AUTOSAR XML (schema 314)
package /ComponentType
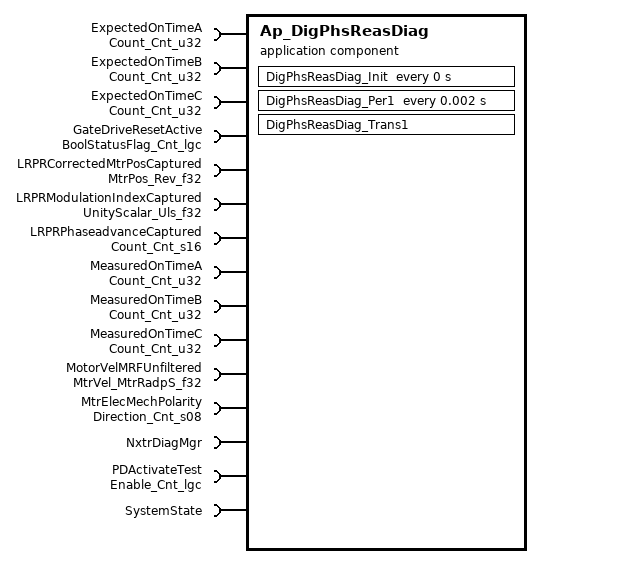
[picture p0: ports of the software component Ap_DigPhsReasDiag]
  application software component type Ap_DigPhsReasDiag
    15 x require port:
      ExpectedOnTimeA: unqueued-receiver-com-spec{data-element=Cnt_u32, init-value=D_ZERO_CNT_U32}, required-interface=Count_Cnt_u32
      ExpectedOnTimeB: unqueued-receiver-com-spec{data-element=Cnt_u32, init-value=D_ZERO_CNT_U32}, required-interface=Count_Cnt_u32
      ExpectedOnTimeC: unqueued-receiver-com-spec{data-element=Cnt_u32, init-value=D_ZERO_CNT_U32}, required-interface=Count_Cnt_u32
      GateDriveResetActive: unqueued-receiver-com-spec{data-element=Cnt_lgc, init-value=D_FALSE_CNT_LGC}, required-interface=BoolStatusFlag_Cnt_lgc
      LRPRCorrectedMtrPosCaptured: unqueued-receiver-com-spec{data-element=Rev_f32, init-value=D_ZERO_ULS_F32}, required-interface=MtrPos_Rev_f32
      LRPRModulationIndexCaptured: unqueued-receiver-com-spec{data-element=Uls_f32, init-value=D_ZERO_ULS_F32}, required-interface=UnityScalar_Uls_f32
      LRPRPhaseadvanceCaptured: unqueued-receiver-com-spec{data-element=Cnt_s16, init-value=D_ZERO_CNT_S16}, required-interface=Count_Cnt_s16
      MeasuredOnTimeA: unqueued-receiver-com-spec{data-element=Cnt_u32, init-value=D_ZERO_CNT_U32}, required-interface=Count_Cnt_u32
      MeasuredOnTimeB: unqueued-receiver-com-spec{data-element=Cnt_u32, init-value=D_ZERO_CNT_U32}, required-interface=Count_Cnt_u32
      MeasuredOnTimeC: unqueued-receiver-com-spec{data-element=Cnt_u32, init-value=D_ZERO_CNT_U32}, required-interface=Count_Cnt_u32
      MotorVelMRFUnfiltered: unqueued-receiver-com-spec{data-element=MtrRadpS_f32, init-value=D_ZERO_ULS_F32}, required-interface=MtrVel_MtrRadpS_f32
      MtrElecMechPolarity: unqueued-receiver-com-spec{data-element=Cnt_s08, init-value=D_ZERO_CNT_S8}, required-interface=Direction_Cnt_s08
      NxtrDiagMgr: required-com-specs=[GetNTCActive, GetNTCFailed, GetNTCStatus, SetNTCStatus], required-interface=NxtrDiagMgr
      PDActivateTest: unqueued-receiver-com-spec{data-element=Cnt_lgc, init-value=D_FALSE_CNT_LGC}, required-interface=Enable_Cnt_lgc
      SystemState: required-interface=SystemState
  internal behavior Ap_DigPhsReasDiag_InternalBehavior: component=Ap_DigPhsReasDiag
    timing event DigPhsReasDiag_InitEvent: start-on-event=DigPhsReasDiag_Init, period=0
    timing event TMT_DigPhsReasDiag_Per1: mode-dependency=dependent-on-mode=[SystemState.Mode.DISABLE, SystemState.Mode.OFF, SystemState.Mode.WARMINIT], start-on-event=DigPhsReasDiag_Per1, period=0.002
    mode switch event MST_DigPhsReasDiag_Trans1_0: start-on-event=DigPhsReasDiag_Trans1, activation=ENTRY, mode=SystemState.Mode.OPERATE
    port-api-options:
      enable-take-address=false, indirect-api=false, port=ExpectedOnTimeA
      enable-take-address=false, indirect-api=false, port=ExpectedOnTimeB
      enable-take-address=false, indirect-api=false, port=ExpectedOnTimeC
      enable-take-address=false, indirect-api=false, port=GateDriveResetActive
      enable-take-address=false, indirect-api=false, port=LRPRCorrectedMtrPosCaptured
      enable-take-address=false, indirect-api=false, port=LRPRModulationIndexCaptured
      enable-take-address=false, indirect-api=false, port=LRPRPhaseadvanceCaptured
      enable-take-address=false, indirect-api=false, port=MeasuredOnTimeA
      enable-take-address=false, indirect-api=false, port=MeasuredOnTimeB
      enable-take-address=false, indirect-api=false, port=MeasuredOnTimeC
      enable-take-address=false, indirect-api=false, port=MotorVelMRFUnfiltered
      enable-take-address=false, indirect-api=false, port=MtrElecMechPolarity
      enable-take-address=false, indirect-api=false, port=NxtrDiagMgr
      enable-take-address=false, indirect-api=false, port=PDActivateTest
      enable-take-address=false, indirect-api=false, port=SystemState
    runnable DigPhsReasDiag_Init
    runnable DigPhsReasDiag_Per1
      13 x data read access:
        READ_ExpectedOnTimeA_Cnt_u32: data-element=ExpectedOnTimeA.Cnt_u32
        READ_ExpectedOnTimeB_Cnt_u32: data-element=ExpectedOnTimeB.Cnt_u32
        READ_ExpectedOnTimeC_Cnt_u32: data-element=ExpectedOnTimeC.Cnt_u32
        READ_GateDriveResetActive_Cnt_lgc: data-element=GateDriveResetActive.Cnt_lgc
        READ_LRPRCorrectedMtrPosCaptured_Rev_f32: data-element=LRPRCorrectedMtrPosCaptured.Rev_f32
        READ_LRPRModulationIndexCaptured_Uls_f32: data-element=LRPRModulationIndexCaptured.Uls_f32
        READ_LRPRPhaseadvanceCaptured_Cnt_s16: data-element=LRPRPhaseadvanceCaptured.Cnt_s16
        READ_MeasuredOnTimeA_Cnt_u32: data-element=MeasuredOnTimeA.Cnt_u32
        READ_MeasuredOnTimeB_Cnt_u32: data-element=MeasuredOnTimeB.Cnt_u32
        READ_MeasuredOnTimeC_Cnt_u32: data-element=MeasuredOnTimeC.Cnt_u32
        READ_MotorVelMRFUnfiltered_MtrRadpS_f32: data-element=MotorVelMRFUnfiltered.MtrRadpS_f32
        READ_MtrElecMechPolarity_Cnt_s08: data-element=MtrElecMechPolarity.Cnt_s08
        READ_PDActivateTest_Cnt_lgc: data-element=PDActivateTest.Cnt_lgc
      sync call SC_NxtrDiagMgr_SetNTCStatus: operation=NxtrDiagMgr.SetNTCStatus, timeout=0
    runnable DigPhsReasDiag_Trans1
  swc implementation Ap_DigPhsReasDiag_Implementation: behavior=Ap_DigPhsReasDiag_InternalBehavior
    code-descriptors:
      code Code: type=SRC
